# DAC12_1 register map
Vendor: Texas Instruments
Peripheral module from a debugger description file (folder msp430).
Registers are 16-bit, read-write, reset 0x0 unless marked. A register's access mark holds for its fields unless they carry their own. Offsets are as the file gives them; lines under a group give offsets from that group; [hi:lo] are bit positions; {n}, {i} and the like mark numbered series; 'fields as' and 'values as' point back to an identical list; <NAME> marks a mode.

## DAC12
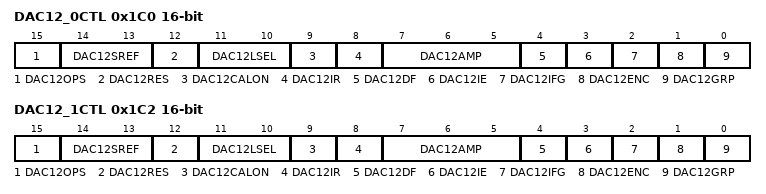
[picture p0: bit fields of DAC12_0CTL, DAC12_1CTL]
0x1C0 DAC12_0CTL — DAC12_0 Control
  [15] DAC12OPS — DAC12 Operation Amp.
  [14:13] DAC12SREF — DAC12 reference bit 0
    0=DAC12 reference 0: Vref+; 1=DAC12 reference 1: Vref+; 2=DAC12 reference 2: Veref+; 3=DAC12 reference 3: Veref+
  [12] DAC12RES — DAC12 resolution
  [11:10] DAC12LSEL — DAC12 load select bit 0
    0=DAC12 load select 0: direct; 1=DAC12 load select 1: latched with DAT; 2=DAC12 load select 2: latched with pos. Timer_A3.OUT1; 3=DAC12 load select 3: latched with pos. Timer_B7.OUT1
  [9] DAC12CALON — DAC12 calibration
  [8] DAC12IR — DAC12 input reference and output range
  [7:5] DAC12AMP — DAC12 amplifier bit 0
    0=DAC12 amplifier 0: off; 1=DAC12 amplifier 1: off; 2=DAC12 amplifier 2: low; 3=DAC12 amplifier 3: low; 4=DAC12 amplifier 4: low; 5=DAC12 amplifier 5: medium; 6=DAC12 amplifier 6: medium; 7=DAC12 amplifier 7: high
  [4] DAC12DF — DAC12 data format
  [3] DAC12IE — DAC12 interrupt enable
  [2] DAC12IFG — DAC12 interrupt flag
  [1] DAC12ENC — DAC12 enable conversion
  [0] DAC12GRP — DAC12 group
0x1C2 DAC12_1CTL — DAC12_1 Control
  fields as DAC12_0CTL
0x1C8 DAC12_0DAT access not given reset not defined — DAC12_0 Data
0x1CA DAC12_1DAT access not given reset not defined — DAC12_1 Data
